// Description:

// Created:

// Author:

// Version:

// Vehicle Project:

LIN_description_file;
LIN_protocol_version = "2.1" ;
LIN_language_version = "2.1" ;
LIN_speed = 19.2 kbps ;
Channel_name = "ATOM_HWLIN4";

Nodes {
  Master: VCU, 5 ms, 0.1 ms ;
  Slaves: GWM ;
}
Signals{
  Vcu_Lin0_TxMsg1_Sig0: 8, 0, VCU, GWM ;
  Vcu_Lin0_TxMsg1_Sig1: 8, 0, VCU, GWM ;
  Vcu_Lin0_TxMsg1_Sig2: 8, 0, VCU, GWM ;
  Vcu_Lin0_TxMsg1_Sig3: 8, 0, VCU, GWM ;
  Vcu_Lin0_TxMsg2_Sig0: 8, 0, VCU, GWM ;
  Vcu_Lin0_TxMsg2_Sig1: 8, 0, VCU, GWM ;
  Vcu_Lin0_TxMsg2_Sig2: 8, 0, VCU, GWM ;
  Vcu_Lin0_TxMsg2_Sig3: 8, 0, VCU, GWM ;
  Vcu_Lin0_RxMsg1_Sig0: 8, 0, GWM, VCU ;
  Vcu_Lin0_RxMsg1_Sig1: 8, 0, GWM, VCU ;
  Vcu_Lin0_RxMsg1_Sig2: 8, 0, GWM, VCU ;
  Vcu_Lin0_RxMsg1_Sig3: 8, 0, GWM, VCU ;
  Vcu_Lin0_RxMsg2_Sig0: 8, 0, GWM, VCU ;
  Vcu_Lin0_RxMsg2_Sig1: 8, 0, GWM, VCU ;
  Vcu_Lin0_RxMsg2_Sig2: 8, 0, GWM, VCU ;
  Vcu_Lin0_RxMsg2_Sig3: 8, 0, GWM, VCU ;
}

Frames{
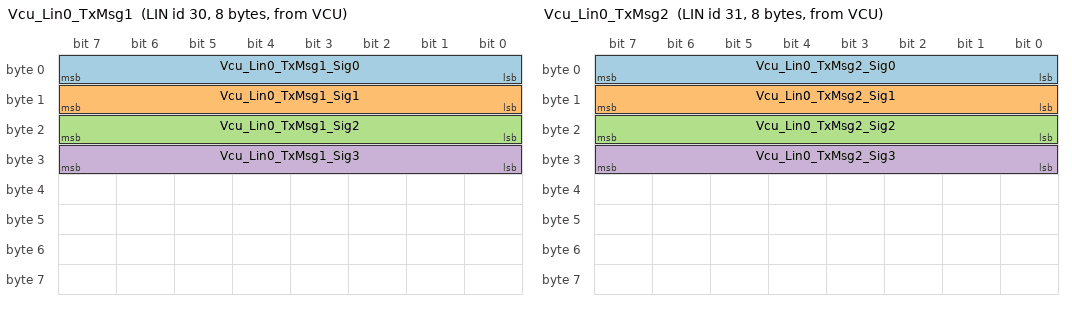
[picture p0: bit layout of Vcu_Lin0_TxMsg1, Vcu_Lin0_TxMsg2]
  Vcu_Lin0_TxMsg1: 30, VCU, 8{
    Vcu_Lin0_TxMsg1_Sig0, 0;
    Vcu_Lin0_TxMsg1_Sig1, 8;
    Vcu_Lin0_TxMsg1_Sig2, 16;
    Vcu_Lin0_TxMsg1_Sig3, 24;
  }
  Vcu_Lin0_TxMsg2: 31, VCU, 8{
    Vcu_Lin0_TxMsg2_Sig0, 0;
    Vcu_Lin0_TxMsg2_Sig1, 8;
    Vcu_Lin0_TxMsg2_Sig2, 16;
    Vcu_Lin0_TxMsg2_Sig3, 24;
  }
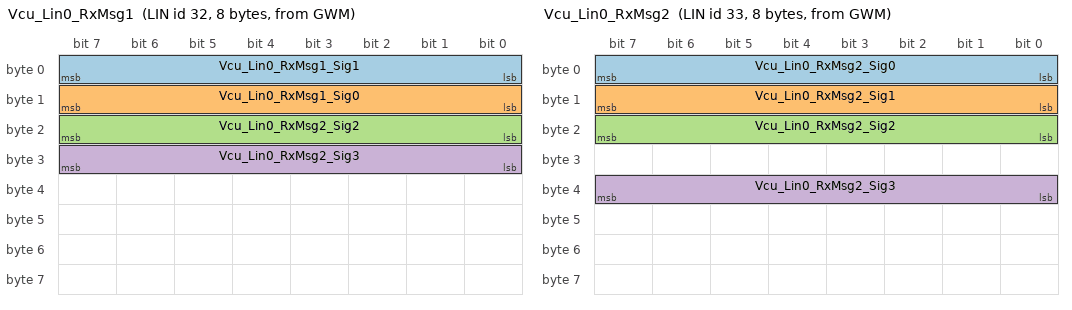
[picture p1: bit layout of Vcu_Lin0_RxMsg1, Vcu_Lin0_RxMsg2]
  Vcu_Lin0_RxMsg1: 32, GWM, 8{
    Vcu_Lin0_RxMsg1_Sig1, 0;
    Vcu_Lin0_RxMsg1_Sig0, 8;
    Vcu_Lin0_RxMsg2_Sig2, 16;
    Vcu_Lin0_RxMsg2_Sig3, 24;
  }
  Vcu_Lin0_RxMsg2: 33, GWM, 8{
    Vcu_Lin0_RxMsg2_Sig0, 0;
    Vcu_Lin0_RxMsg2_Sig1, 8;
    Vcu_Lin0_RxMsg2_Sig2, 16;
    Vcu_Lin0_RxMsg2_Sig3, 32;
  }
}

Node_attributes {
  GWM{
    LIN_protocol = "2.1" ;
    configured_NAD = 0x52 ;
    initial_NAD = 0x52 ;
    product_id = 0x0, 0x0, 0x0 ;
    P2_min = 50 ms ;
    ST_min = 0 ms ;
    N_As_timeout = 1000 ms ;
    N_Cr_timeout = 1000 ms ;
    configurable_frames{
      Vcu_Lin0_TxMsg1 ;
      Vcu_Lin0_TxMsg2 ;
      Vcu_Lin0_RxMsg1 ;
      Vcu_Lin0_RxMsg2 ;
    }
  }
}

Schedule_tables {
 Vcu_Lin0_Schedule{
  Vcu_Lin0_TxMsg1 delay 20 ms ;
  Vcu_Lin0_TxMsg2 delay 20 ms ;
  Vcu_Lin0_RxMsg1 delay 20 ms ;
  Vcu_Lin0_RxMsg2 delay 20 ms ;
 }
}
